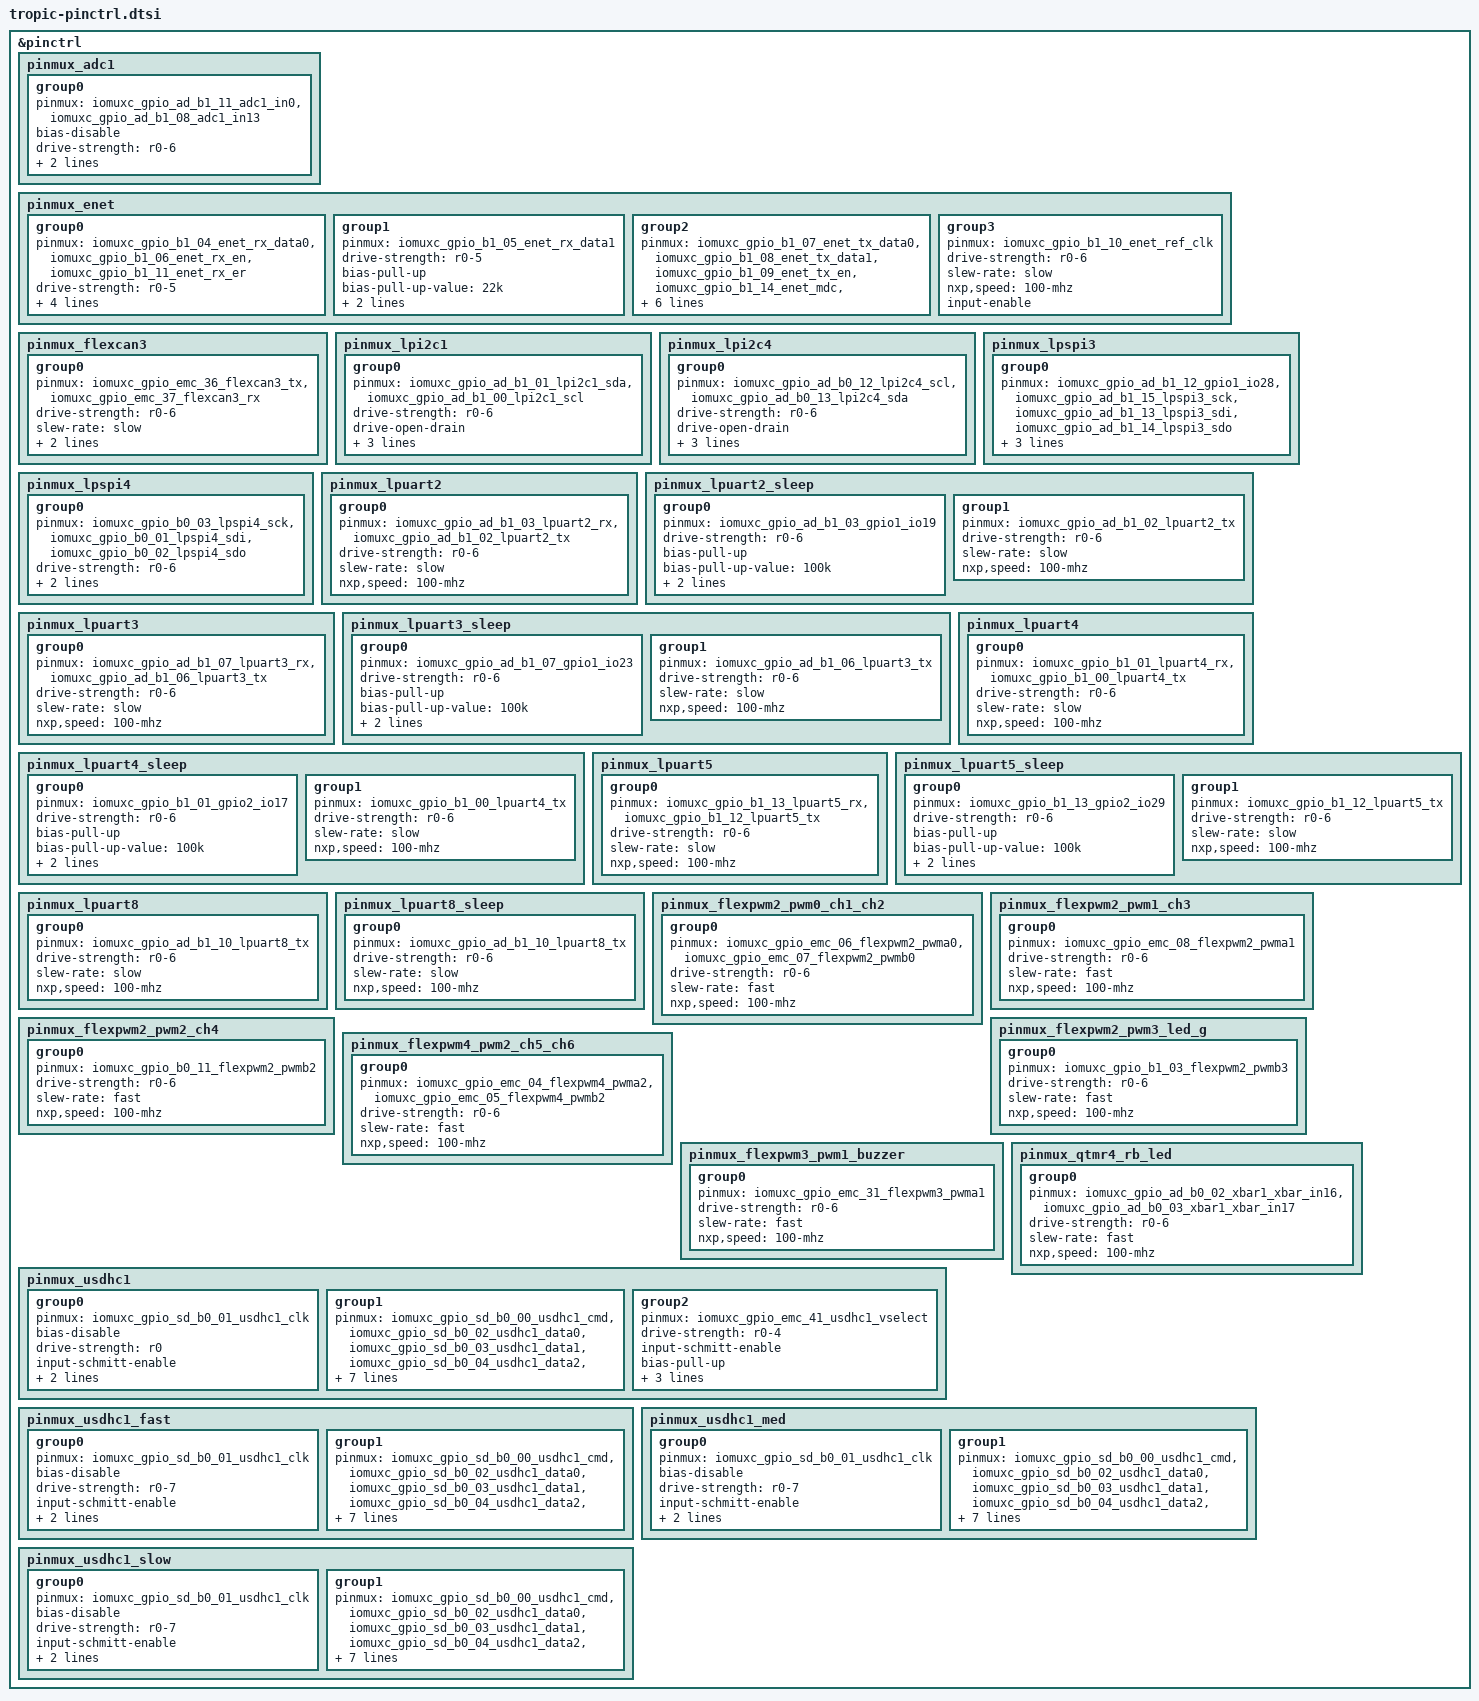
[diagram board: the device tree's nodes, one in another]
/*
 * Copyright (c) 2022, NXP
 * SPDX-License-Identifier: Apache-2.0
 *
 * Note: File generated by rt_cfg_utils.py
 * from teensy4.mex
 */

#include <nxp/nxp_imx/rt/mimxrt1062dvl6a-pinctrl.dtsi>

&pinctrl {
	/* ADC1 inputs 0 and 13 */
	pinmux_adc1: pinmux_adc1 {
		group0 {
			pinmux = <&iomuxc_gpio_ad_b1_11_adc1_in0>,
				<&iomuxc_gpio_ad_b1_08_adc1_in13>;
			bias-disable;
			drive-strength = "r0-6";
			slew-rate = "slow";
			nxp,speed = "100-mhz";
		};
	};

	/* Mode Straps configuration DP83825 */
	pinmux_enet: pinmux_enet {
		group0 {
			pinmux = <&iomuxc_gpio_b1_04_enet_rx_data0>,
				<&iomuxc_gpio_b1_06_enet_rx_en>,
				<&iomuxc_gpio_b1_11_enet_rx_er>;
			drive-strength = "r0-5";
			bias-pull-down;
			bias-pull-down-value = "100k";
			slew-rate = "fast";
			nxp,speed = "200-mhz";
		};
		group1 {
			pinmux = <&iomuxc_gpio_b1_05_enet_rx_data1>;
			drive-strength = "r0-5";
			bias-pull-up;
			bias-pull-up-value = "22k";
			slew-rate = "fast";
			nxp,speed = "200-mhz";
		};
		group2 {
			pinmux = <&iomuxc_gpio_b1_07_enet_tx_data0>,
				<&iomuxc_gpio_b1_08_enet_tx_data1>,
				<&iomuxc_gpio_b1_09_enet_tx_en>,
				<&iomuxc_gpio_b1_14_enet_mdc>,
				<&iomuxc_gpio_b1_15_enet_mdio>,
				<&iomuxc_gpio_b0_15_gpio2_io15>,
				<&iomuxc_gpio_b0_14_gpio2_io14>;
			drive-strength = "r0-6";
			slew-rate = "slow";
			nxp,speed = "100-mhz";
		};
		group3 {
			pinmux = <&iomuxc_gpio_b1_10_enet_ref_clk>;
			drive-strength = "r0-6";
			slew-rate = "slow";
			nxp,speed = "100-mhz";
			input-enable;
		};
	};

	/* FLEXCAN3 TX, RX on Teensy-Pins 31/30 */
	pinmux_flexcan3: pinmux_flexcan3 {
		group0 {
			pinmux = <&iomuxc_gpio_emc_36_flexcan3_tx>,
				<&iomuxc_gpio_emc_37_flexcan3_rx>;
			drive-strength = "r0-6";
			slew-rate = "slow";
			nxp,speed = "100-mhz";
			input-enable;
		};
	};

	/* LPI2C1 SCL, SDA on Teensy-Pins 19/18 */
	pinmux_lpi2c1: pinmux_lpi2c1 {
		group0 {
			pinmux = <&iomuxc_gpio_ad_b1_01_lpi2c1_sda>,
				<&iomuxc_gpio_ad_b1_00_lpi2c1_scl>;
			drive-strength = "r0-6";
			drive-open-drain;
			slew-rate = "slow";
			nxp,speed = "100-mhz";
			input-enable;
		};
	};

	/* LPI2C4 SCL, SDA on Teensy-Pins 24/25 */
	pinmux_lpi2c4: pinmux_lpi2c4 {
		group0 {
			pinmux = <&iomuxc_gpio_ad_b0_12_lpi2c4_scl>,
				<&iomuxc_gpio_ad_b0_13_lpi2c4_sda>;
			drive-strength = "r0-6";
			drive-open-drain;
			slew-rate = "slow";
			nxp,speed = "100-mhz";
			input-enable;
		};
	};

	/* LPSPI3 MISO, MOSI, SCK, CS on Teensy-Pins 39/26/27/38 */
	pinmux_lpspi3: pinmux_lpspi3 {
		group0 {
			pinmux = <&iomuxc_gpio_ad_b1_12_gpio1_io28>,
			    <&iomuxc_gpio_ad_b1_15_lpspi3_sck>,
				<&iomuxc_gpio_ad_b1_13_lpspi3_sdi>,
				<&iomuxc_gpio_ad_b1_14_lpspi3_sdo>;
			drive-strength = "r0-6";
			slew-rate = "slow";
			nxp,speed = "100-mhz";
		};
	};

	/* LPSPI4 MISO, MOSI, SCK, CS, CS2 on Teensy-Pins 12/11/13/10/36 */
	pinmux_lpspi4: pinmux_lpspi4 {
		group0 {
			pinmux = <&iomuxc_gpio_b0_03_lpspi4_sck>,
				<&iomuxc_gpio_b0_01_lpspi4_sdi>,
				<&iomuxc_gpio_b0_02_lpspi4_sdo>;
			drive-strength = "r0-6";
			slew-rate = "slow";
			nxp,speed = "100-mhz";
		};
	};

	/* LPUART2 TX/RX on Teensy-Pins 14/15 */
	pinmux_lpuart2: pinmux_lpuart2 {
		group0 {
			pinmux = <&iomuxc_gpio_ad_b1_03_lpuart2_rx>,
				<&iomuxc_gpio_ad_b1_02_lpuart2_tx>;
			drive-strength = "r0-6";
			slew-rate = "slow";
			nxp,speed = "100-mhz";
		};
	};

	pinmux_lpuart2_sleep: pinmux_lpuart2_sleep {
		group0 {
			pinmux = <&iomuxc_gpio_ad_b1_03_gpio1_io19>;
			drive-strength = "r0-6";
			bias-pull-up;
			bias-pull-up-value = "100k";
			slew-rate = "slow";
			nxp,speed = "100-mhz";
		};
		group1 {
			pinmux = <&iomuxc_gpio_ad_b1_02_lpuart2_tx>;
			drive-strength = "r0-6";
			slew-rate = "slow";
			nxp,speed = "100-mhz";
		};
	};

	/* LPUART3 TX/RX on Teensy-Pins 17/16 */
	pinmux_lpuart3: pinmux_lpuart3 {
		group0 {
			pinmux = <&iomuxc_gpio_ad_b1_07_lpuart3_rx>,
				<&iomuxc_gpio_ad_b1_06_lpuart3_tx>;
			drive-strength = "r0-6";
			slew-rate = "slow";
			nxp,speed = "100-mhz";
		};
	};

	pinmux_lpuart3_sleep: pinmux_lpuart3_sleep {
		group0 {
			pinmux = <&iomuxc_gpio_ad_b1_07_gpio1_io23>;
			drive-strength = "r0-6";
			bias-pull-up;
			bias-pull-up-value = "100k";
			slew-rate = "slow";
			nxp,speed = "100-mhz";
		};
		group1 {
			pinmux = <&iomuxc_gpio_ad_b1_06_lpuart3_tx>;
			drive-strength = "r0-6";
			slew-rate = "slow";
			nxp,speed = "100-mhz";
		};
	};

	/* LPUART4 TX/RX on Teensy-Pins 8/7 */
	pinmux_lpuart4: pinmux_lpuart4 {
		group0 {
			pinmux = <&iomuxc_gpio_b1_01_lpuart4_rx>,
				<&iomuxc_gpio_b1_00_lpuart4_tx>;
			drive-strength = "r0-6";
			slew-rate = "slow";
			nxp,speed = "100-mhz";
		};
	};

	pinmux_lpuart4_sleep: pinmux_lpuart4_sleep {
		group0 {
			pinmux = <&iomuxc_gpio_b1_01_gpio2_io17>;
			drive-strength = "r0-6";
			bias-pull-up;
			bias-pull-up-value = "100k";
			slew-rate = "slow";
			nxp,speed = "100-mhz";
		};
		group1 {
			pinmux = <&iomuxc_gpio_b1_00_lpuart4_tx>;
			drive-strength = "r0-6";
			slew-rate = "slow";
			nxp,speed = "100-mhz";
		};
	};

	/* LPUART5 TX/RX on Teensy-Pins 35/34 */
	pinmux_lpuart5: pinmux_lpuart5 {
		group0 {
			pinmux = <&iomuxc_gpio_b1_13_lpuart5_rx>,
				<&iomuxc_gpio_b1_12_lpuart5_tx>;
			drive-strength = "r0-6";
			slew-rate = "slow";
			nxp,speed = "100-mhz";
		};
	};

	pinmux_lpuart5_sleep: pinmux_lpuart5_sleep {
		group0 {
			pinmux = <&iomuxc_gpio_b1_13_gpio2_io29>;
			drive-strength = "r0-6";
			bias-pull-up;
			bias-pull-up-value = "100k";
			slew-rate = "slow";
			nxp,speed = "100-mhz";
		};
		group1 {
			pinmux = <&iomuxc_gpio_b1_12_lpuart5_tx>;
			drive-strength = "r0-6";
			slew-rate = "slow";
			nxp,speed = "100-mhz";
		};
	};

	/* LPUART8 Single-duplex on Teensy-Pin 20 */
	pinmux_lpuart8: pinmux_lpuart8 {
		group0 {
			pinmux = <&iomuxc_gpio_ad_b1_10_lpuart8_tx>;
			drive-strength = "r0-6";
			slew-rate = "slow";
			nxp,speed = "100-mhz";
		};
	};

	pinmux_lpuart8_sleep: pinmux_lpuart8_sleep {
		group0 {
			pinmux = <&iomuxc_gpio_ad_b1_10_lpuart8_tx>;
			drive-strength = "r0-6";
			slew-rate = "slow";
			nxp,speed = "100-mhz";
		};
	};
	
	/* pwm pins for vmu and io ports */
	pinmux_flexpwm2_pwm0_ch1_ch2: pinmux_flexpwm2_pwm0_ch1_ch2 {
		group0 {
			pinmux = <&iomuxc_gpio_emc_06_flexpwm2_pwma0>,
					<&iomuxc_gpio_emc_07_flexpwm2_pwmb0>;
			drive-strength = "r0-6";
			slew-rate = "fast";
			nxp,speed = "100-mhz";
		};
	};

	pinmux_flexpwm2_pwm1_ch3: pinmux_flexpwm2_pwm1_ch3 {
		group0 {
			pinmux = <&iomuxc_gpio_emc_08_flexpwm2_pwma1>;
			drive-strength = "r0-6";
			slew-rate = "fast";
			nxp,speed = "100-mhz";
		};
	};

	pinmux_flexpwm2_pwm2_ch4: pinmux_flexpwm2_pwm2_ch4 {
		group0 {
			pinmux = <&iomuxc_gpio_b0_11_flexpwm2_pwmb2>;
			drive-strength = "r0-6";
			slew-rate = "fast";
			nxp,speed = "100-mhz";
		};
	};

	pinmux_flexpwm2_pwm3_led_g: pinmux_flexpwm2_pwm3_led_g {
		group0 {
			pinmux = <&iomuxc_gpio_b1_03_flexpwm2_pwmb3>;
			drive-strength = "r0-6";
			slew-rate = "fast";
			nxp,speed = "100-mhz";
		};
	};

	pinmux_flexpwm4_pwm2_ch5_ch6: pinmux_flexpwm4_pwm2_ch5_ch6 {
		group0 {
			pinmux = <&iomuxc_gpio_emc_04_flexpwm4_pwma2>,
					<&iomuxc_gpio_emc_05_flexpwm4_pwmb2>;
			drive-strength = "r0-6";
			slew-rate = "fast";
			nxp,speed = "100-mhz";
		};
	};

	pinmux_flexpwm3_pwm1_buzzer: pinmux_flexpwm3_pwm1_buzzer {
		group0 {
			pinmux = <&iomuxc_gpio_emc_31_flexpwm3_pwma1>;
			drive-strength = "r0-6";
			slew-rate = "fast";
			nxp,speed = "100-mhz";
		};
	};

	pinmux_qtmr4_rb_led: pinmux_qtmr4_rb_led {
		group0 {
			pinmux = <&iomuxc_gpio_ad_b0_02_xbar1_xbar_in16>,
					<&iomuxc_gpio_ad_b0_03_xbar1_xbar_in17>;
			drive-strength = "r0-6";
			slew-rate = "fast";
			nxp,speed = "100-mhz";
		};
	};

	pinmux_usdhc1: pinmux_usdhc1 {
		group0 {
			pinmux = <&iomuxc_gpio_sd_b0_01_usdhc1_clk>;
			bias-disable;
			drive-strength = "r0";
			input-schmitt-enable;
			slew-rate = "fast";
			nxp,speed = "100-mhz";
		};
		group1 {
			pinmux = <&iomuxc_gpio_sd_b0_00_usdhc1_cmd>,
				<&iomuxc_gpio_sd_b0_02_usdhc1_data0>,
				<&iomuxc_gpio_sd_b0_03_usdhc1_data1>,
				<&iomuxc_gpio_sd_b0_04_usdhc1_data2>,
				<&iomuxc_gpio_sd_b0_05_usdhc1_data3>;
			drive-strength = "r0";
			input-schmitt-enable;
			bias-pull-up;
			bias-pull-up-value = "47k";
			slew-rate = "fast";
			nxp,speed = "100-mhz";
		};
		group2 {
			pinmux = <&iomuxc_gpio_emc_41_usdhc1_vselect>;
			drive-strength = "r0-4";
			input-schmitt-enable;
			bias-pull-up;
			bias-pull-up-value = "47k";
			slew-rate = "fast";
			nxp,speed = "100-mhz";
		};
	};

	/* fast pinmux settings for USDHC (over 100 Mhz) */
	pinmux_usdhc1_fast: pinmux_usdhc1_fast {
		group0 {
			pinmux = <&iomuxc_gpio_sd_b0_01_usdhc1_clk>;
			bias-disable;
			drive-strength = "r0-7";
			input-schmitt-enable;
			slew-rate = "fast";
			nxp,speed = "200-mhz";
		};
		group1 {
			pinmux = <&iomuxc_gpio_sd_b0_00_usdhc1_cmd>,
				<&iomuxc_gpio_sd_b0_02_usdhc1_data0>,
				<&iomuxc_gpio_sd_b0_03_usdhc1_data1>,
				<&iomuxc_gpio_sd_b0_04_usdhc1_data2>,
				<&iomuxc_gpio_sd_b0_05_usdhc1_data3>;
			drive-strength = "r0-7";
			input-schmitt-enable;
			bias-pull-up;
			bias-pull-up-value = "47k";
			slew-rate = "fast";
			nxp,speed = "200-mhz";
		};
	};

	/* medium pinmux settings for USDHC (under 100 Mhz) */
	pinmux_usdhc1_med: pinmux_usdhc1_med {
		group0 {
			pinmux = <&iomuxc_gpio_sd_b0_01_usdhc1_clk>;
			bias-disable;
			drive-strength = "r0-7";
			input-schmitt-enable;
			slew-rate = "fast";
			nxp,speed = "100-mhz";
		};
		group1 {
			pinmux = <&iomuxc_gpio_sd_b0_00_usdhc1_cmd>,
				<&iomuxc_gpio_sd_b0_02_usdhc1_data0>,
				<&iomuxc_gpio_sd_b0_03_usdhc1_data1>,
				<&iomuxc_gpio_sd_b0_04_usdhc1_data2>,
				<&iomuxc_gpio_sd_b0_05_usdhc1_data3>;
			drive-strength = "r0-7";
			input-schmitt-enable;
			bias-pull-up;
			bias-pull-up-value = "47k";
			slew-rate = "fast";
			nxp,speed = "100-mhz";
		};
	};

	/* slow pinmux settings for USDHC (under 50 Mhz) */
	pinmux_usdhc1_slow: pinmux_usdhc1_slow {
		group0 {
			pinmux = <&iomuxc_gpio_sd_b0_01_usdhc1_clk>;
			bias-disable;
			drive-strength = "r0-7";
			input-schmitt-enable;
			slew-rate = "fast";
			nxp,speed = "50-mhz";
		};
		group1 {
			pinmux = <&iomuxc_gpio_sd_b0_00_usdhc1_cmd>,
				<&iomuxc_gpio_sd_b0_02_usdhc1_data0>,
				<&iomuxc_gpio_sd_b0_03_usdhc1_data1>,
				<&iomuxc_gpio_sd_b0_04_usdhc1_data2>,
				<&iomuxc_gpio_sd_b0_05_usdhc1_data3>;
			drive-strength = "r0-7";
			input-schmitt-enable;
			bias-pull-up;
			bias-pull-up-value = "47k";
			slew-rate = "fast";
			nxp,speed = "50-mhz";
		};
	};

};

